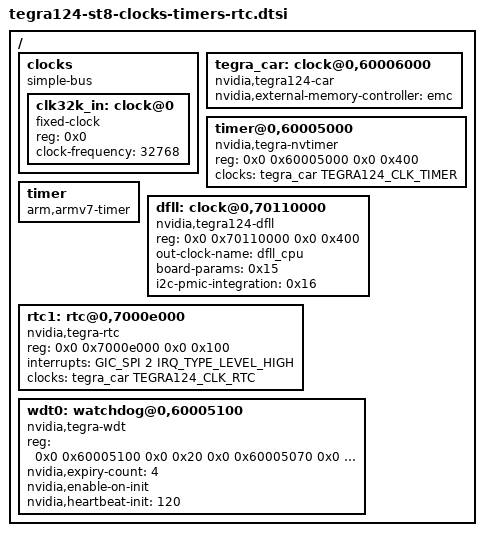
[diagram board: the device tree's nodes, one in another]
/ {
    clocks {
        compatible = "simple-bus";
        #address-cells = <0x1>;
        #size-cells = <0x0>;
        status = "okay";

        clk32k_in: clock@0 {
            compatible = "fixed-clock";
            reg = <0x0>;
            #clock-cells = <0x0>;
            clock-frequency = <32768>;
        };
    };
    
    tegra_car: clock@0,60006000 {
        compatible = "nvidia,tegra124-car";
        #clock-cells = <1>;
        #reset-cells = <1>;
        nvidia,external-memory-controller = <&emc>;
        status = "okay";
    };
    
    timer@0,60005000 {
        compatible = "nvidia,tegra-nvtimer";
        reg = <0x0 0x60005000 0x0 0x400>;
        clocks = <&tegra_car TEGRA124_CLK_TIMER>;
        status = "okay";
    };
    
    timer {
        compatible = "arm,armv7-timer";
    };
    
    dfll: clock@0,70110000 {
        compatible = "nvidia,tegra124-dfll";
        reg = <0x0 0x70110000 0x0 0x400>;
        out-clock-name = "dfll_cpu";
        status = "okay";
        board-params = <0x15>;
        i2c-pmic-integration = <0x16>;
    };
    
    rtc1: rtc@0,7000e000 {
        compatible = "nvidia,tegra-rtc";
        reg = <0x0 0x7000e000 0x0 0x100>;
        interrupts = <GIC_SPI 2 IRQ_TYPE_LEVEL_HIGH>;
        clocks = <&tegra_car TEGRA124_CLK_RTC>;
        status = "okay";
    };
    
    wdt0: watchdog@0,60005100 {
        compatible = "nvidia,tegra-wdt";
        reg = <0x0 0x60005100 0x0 0x20 0x0 0x60005070 0x0 0x8>;
        nvidia,expiry-count = <4>;
        nvidia,enable-on-init;
        nvidia,heartbeat-init = <120>;
    };
};
